VERSION ""

NS_ :

BS_:

BU_: Inverters_Front Inverters_Rear

BO_ 177 AP_ETAS_EnableInv: 8 Vector__XXX
 SG_ Enable_Inv_R : 0|1@0+ (1,0) [0|1] "-"  Inverters_Rear

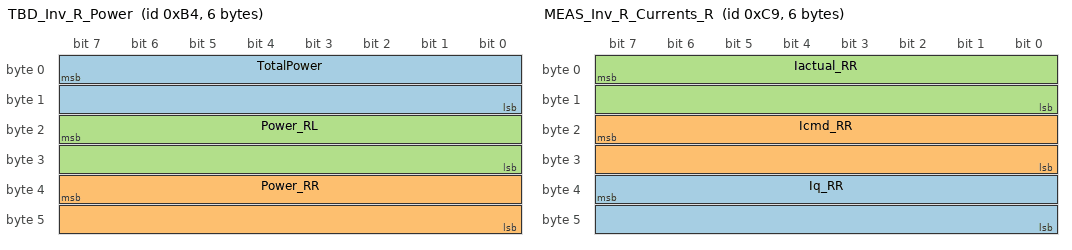
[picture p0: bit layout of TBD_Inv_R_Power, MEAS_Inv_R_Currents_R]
BO_ 180 TBD_Inv_R_Power: 6 Inverters_Rear
 SG_ TotalPower : 7|16@0+ (1,0) [0|65535] "kW" Vector__XXX
 SG_ Power_RR : 39|16@0+ (1,0) [0|65535] "kW" Vector__XXX
 SG_ Power_RL : 23|16@0+ (1,0) [0|65535] "kW" Vector__XXX

BO_ 199 TBD_Inv_R_Torque: 4 Inverters_Rear
 SG_ TorqueReal_RR : 23|16@0+ (1,0) [0|65535] "Nm" Vector__XXX
 SG_ TorqueReal_RL : 7|16@0+ (1,0) [0|65535] "Nm" Vector__XXX

BO_ 176 AP_Inv_R_Error: 8 Inverters_Rear

BO_ 181 AP_Inv_R_Speed: 4 Inverters_Rear
 SG_ SpeedMotor_RR : 23|16@0+ (1,0) [0|65535] "rpm" Vector__XXX
 SG_ SpeedMotor_RL : 7|16@0+ (1,0) [0|65535] "rpm" Vector__XXX

BO_ 179 AP_Inv_R_DCBus: 4 Inverters_Rear
 SG_ DCBus_RR : 23|16@0+ (1,0) [0|65535] "V" Vector__XXX
 SG_ DCBus_RL : 7|16@0+ (1,0) [0|65535] "V" Vector__XXX

BO_ 201 MEAS_Inv_R_Currents_R: 6 Inverters_Rear
 SG_ Iq_RR : 39|16@0+ (1,0) [0|65535] "A" Vector__XXX
 SG_ Icmd_RR : 23|16@0+ (1,0) [0|65535] "A" Vector__XXX
 SG_ Iactual_RR : 7|16@0+ (1,0) [0|65535] "A" Vector__XXX

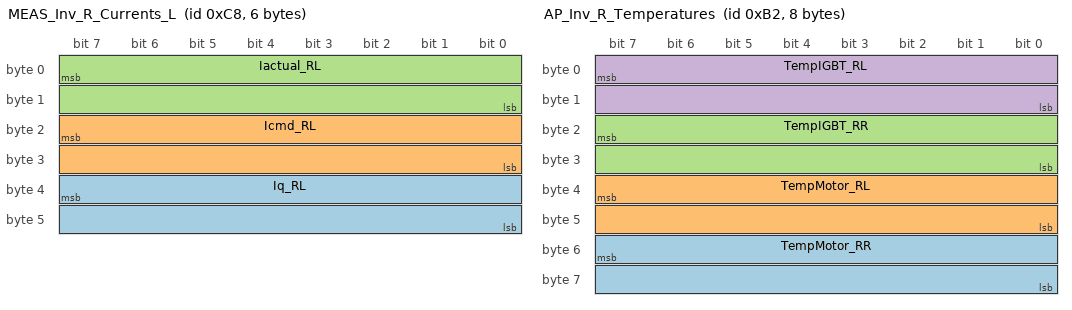
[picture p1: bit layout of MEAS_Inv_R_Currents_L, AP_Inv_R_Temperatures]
BO_ 200 MEAS_Inv_R_Currents_L: 6 Inverters_Rear
 SG_ Iq_RL : 39|16@0+ (1,0) [0|65535] "A" Vector__XXX
 SG_ Icmd_RL : 23|16@0+ (1,0) [0|65535] "A" Vector__XXX
 SG_ Iactual_RL : 7|16@0+ (1,0) [0|65535] "A" Vector__XXX

BO_ 178 AP_Inv_R_Temperatures: 8 Inverters_Rear
 SG_ TempMotor_RR : 55|16@0+ (1,0) [0|65535] "ºC" Vector__XXX
 SG_ TempMotor_RL : 39|16@0+ (1,0) [0|65535] "ºC" Vector__XXX
 SG_ TempIGBT_RR : 23|16@0+ (1,0) [0|65535] "ºC" Vector__XXX
 SG_ TempIGBT_RL : 7|16@0+ (1,0) [0|65535] "ºC" Vector__XXX
